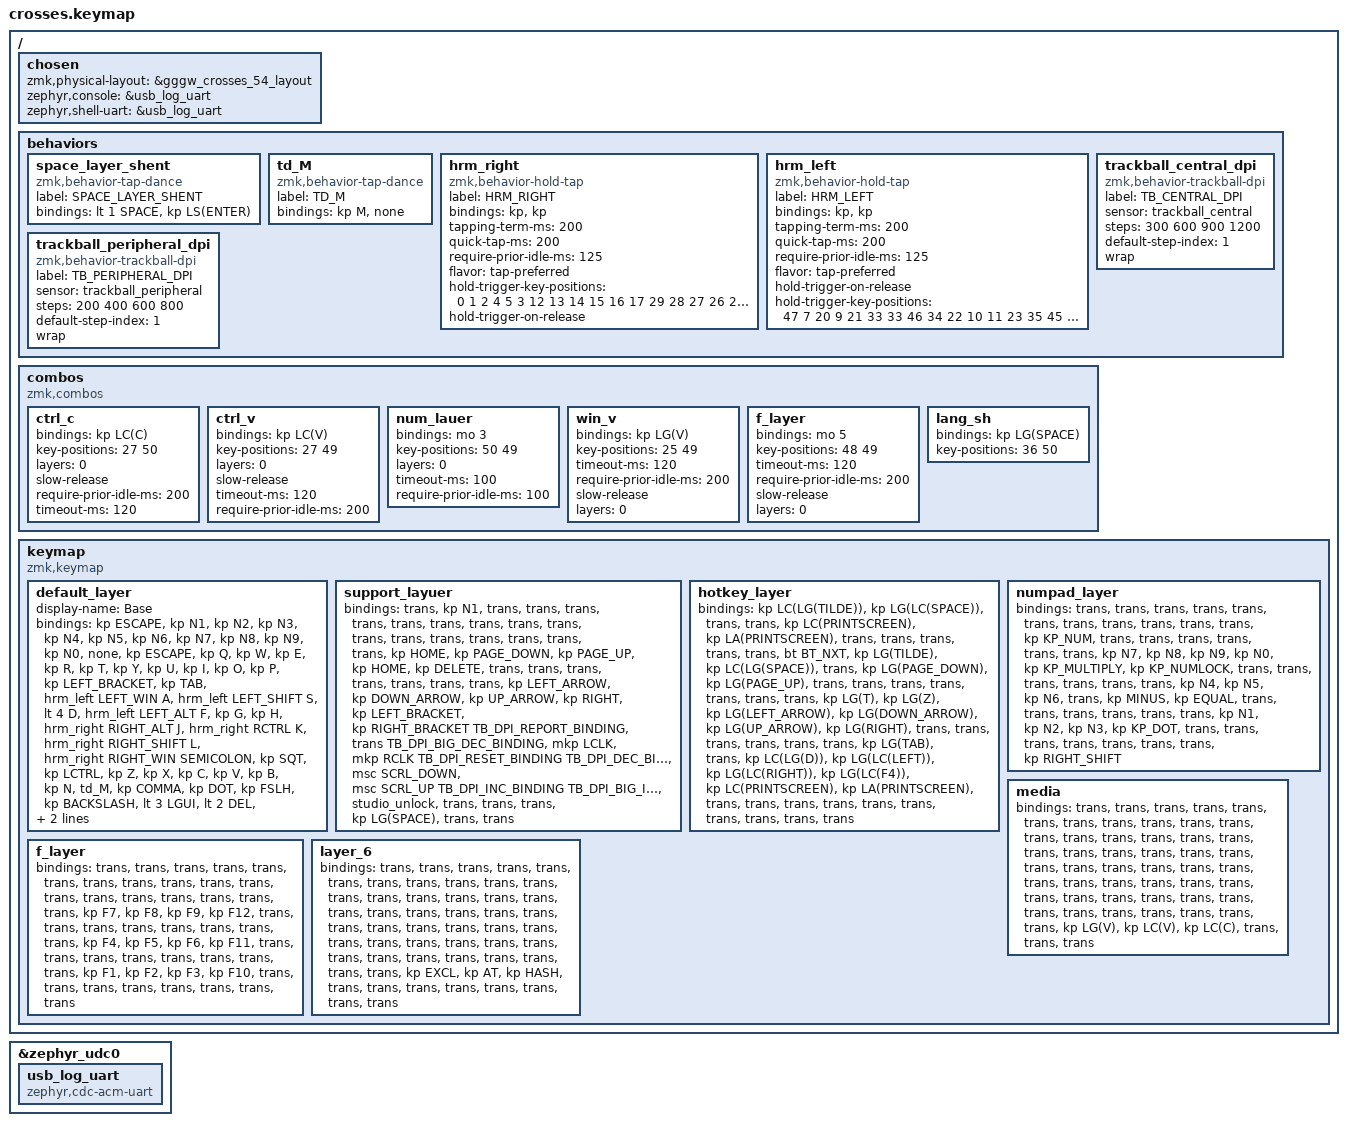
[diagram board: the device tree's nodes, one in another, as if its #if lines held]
#include <behaviors.dtsi>
#include <dt-bindings/zmk/bt.h>
#include <dt-bindings/zmk/keys.h>
#include <dt-bindings/zmk/pointing.h>
#include <dt-bindings/zmk/trackball_dpi.h>
#include <interfaces/hid-trackball.dtsi>

/ {
#define TB_DPI_BEHAVIOR &trans
#define TB_DPI_DEC_BINDING TB_DPI_BEHAVIOR
#define TB_DPI_INC_BINDING TB_DPI_BEHAVIOR
#define TB_DPI_RESET_BINDING TB_DPI_BEHAVIOR
#define TB_DPI_BIG_DEC_BINDING TB_DPI_BEHAVIOR
#define TB_DPI_BIG_INC_BINDING TB_DPI_BEHAVIOR
#define TB_DPI_REPORT_BINDING TB_DPI_BEHAVIOR

#if defined(CONFIG_ZMK_SPLIT_ROLE_CENTRAL)
#undef TB_DPI_BEHAVIOR
#undef TB_DPI_DEC_BINDING
#undef TB_DPI_INC_BINDING
#undef TB_DPI_RESET_BINDING
#undef TB_DPI_BIG_DEC_BINDING
#undef TB_DPI_BIG_INC_BINDING
#undef TB_DPI_REPORT_BINDING
#define TB_DPI_BEHAVIOR &trackball_central_dpi
#define TB_DPI_DEC_BINDING TB_DPI_BEHAVIOR ZMK_TRACKBALL_DPI_CMD_STEP_DOWN 1
#define TB_DPI_INC_BINDING TB_DPI_BEHAVIOR ZMK_TRACKBALL_DPI_CMD_STEP_UP 1
#define TB_DPI_RESET_BINDING TB_DPI_BEHAVIOR ZMK_TRACKBALL_DPI_CMD_RESET 0
#define TB_DPI_BIG_DEC_BINDING TB_DPI_BEHAVIOR ZMK_TRACKBALL_DPI_CMD_STEP_DOWN 2
#define TB_DPI_BIG_INC_BINDING TB_DPI_BEHAVIOR ZMK_TRACKBALL_DPI_CMD_STEP_UP 2
#define TB_DPI_REPORT_BINDING TB_DPI_BEHAVIOR ZMK_TRACKBALL_DPI_CMD_REPORT 0
#elif defined(CONFIG_ZMK_SPLIT_ROLE_PERIPHERAL)
#undef TB_DPI_BEHAVIOR
#undef TB_DPI_DEC_BINDING
#undef TB_DPI_INC_BINDING
#undef TB_DPI_RESET_BINDING
#undef TB_DPI_BIG_DEC_BINDING
#undef TB_DPI_BIG_INC_BINDING
#undef TB_DPI_REPORT_BINDING
#define TB_DPI_BEHAVIOR &trackball_peripheral_dpi
#define TB_DPI_DEC_BINDING TB_DPI_BEHAVIOR ZMK_TRACKBALL_DPI_CMD_STEP_DOWN 1
#define TB_DPI_INC_BINDING TB_DPI_BEHAVIOR ZMK_TRACKBALL_DPI_CMD_STEP_UP 1
#define TB_DPI_RESET_BINDING TB_DPI_BEHAVIOR ZMK_TRACKBALL_DPI_CMD_RESET 0
#define TB_DPI_BIG_DEC_BINDING TB_DPI_BEHAVIOR ZMK_TRACKBALL_DPI_CMD_STEP_DOWN 2
#define TB_DPI_BIG_INC_BINDING TB_DPI_BEHAVIOR ZMK_TRACKBALL_DPI_CMD_STEP_UP 2
#define TB_DPI_REPORT_BINDING TB_DPI_BEHAVIOR ZMK_TRACKBALL_DPI_CMD_REPORT 0
#endif

    chosen {
        zmk,physical-layout = &gggw_crosses_54_layout;
        zephyr,console = &usb_log_uart;
        zephyr,shell-uart = &usb_log_uart;
    };

    behaviors {
        space_layer_shent: space_layer_shent {
            compatible = "zmk,behavior-tap-dance";
            label = "SPACE_LAYER_SHENT";
            #binding-cells = <0>;
            bindings = <&lt 1 SPACE>, <&kp LS(ENTER)>;
        };

        td_M: td_M {
            compatible = "zmk,behavior-tap-dance";
            label = "TD_M";
            #binding-cells = <0>;
            bindings = <&kp M>, <&none>;
        };

        hrm_right: hrm_right {
            compatible = "zmk,behavior-hold-tap";
            label = "HRM_RIGHT";
            bindings = <&kp>, <&kp>;

            #binding-cells = <2>;
            tapping-term-ms = <200>;
            quick-tap-ms = <200>;
            require-prior-idle-ms = <125>;
            flavor = "tap-preferred";
            hold-trigger-key-positions = <0 1 2 4 5 3 12 13 14 15 16 17 29 28 27 26 25 24 36 37 38 39 40 41 48 49 50>;
            hold-trigger-on-release;
        };

        hrm_left: hrm_left {
            compatible = "zmk,behavior-hold-tap";
            label = "HRM_LEFT";
            bindings = <&kp>, <&kp>;

            #binding-cells = <2>;
            tapping-term-ms = <200>;
            quick-tap-ms = <200>;
            require-prior-idle-ms = <125>;
            flavor = "tap-preferred";
            hold-trigger-on-release;
            hold-trigger-key-positions = <47 7 20 9 21 33 33 46 34 22 10 11 23 35 45 8 32 44 43 42 30 31 19 18 6 51 52 53>;
        };

#if defined(CONFIG_SHIELD_CROSSES_RIGHT)
        trackball_central_dpi: trackball_central_dpi {
            compatible = "zmk,behavior-trackball-dpi";
            label = "TB_CENTRAL_DPI";
            #binding-cells = <2>;
            sensor = <&trackball_central>;
            steps = <300 600 900 1200>;
            default-step-index = <1>;
            wrap;
        };
#endif

#if defined(CONFIG_SHIELD_CROSSES_LEFT)
        trackball_peripheral_dpi: trackball_peripheral_dpi {
            compatible = "zmk,behavior-trackball-dpi";
            label = "TB_PERIPHERAL_DPI";
            #binding-cells = <2>;
            sensor = <&trackball_peripheral>;
            steps = <200 400 600 800>;
            default-step-index = <1>;
            wrap;
        };
#endif
    };

    combos {
        compatible = "zmk,combos";

        ctrl_c {
            bindings = <&kp LC(C)>;
            key-positions = <27 50>;
            layers = <0>;
            slow-release;
            require-prior-idle-ms = <200>;
            timeout-ms = <120>;
        };

        ctrl_v {
            bindings = <&kp LC(V)>;
            key-positions = <27 49>;
            layers = <0>;
            slow-release;
            timeout-ms = <120>;
            require-prior-idle-ms = <200>;
        };

        num_lauer {
            bindings = <&mo 3>;
            key-positions = <50 49>;
            layers = <0>;
            timeout-ms = <100>;
            require-prior-idle-ms = <100>;
        };

        win_v {
            bindings = <&kp LG(V)>;
            key-positions = <25 49>;
            timeout-ms = <120>;
            require-prior-idle-ms = <200>;
            slow-release;
            layers = <0>;
        };

        f_layer {
            bindings = <&mo 5>;
            key-positions = <48 49>;
            timeout-ms = <120>;
            require-prior-idle-ms = <200>;
            slow-release;
            layers = <0>;
        };

        lang_sh {
            bindings = <&kp LG(SPACE)>;
            key-positions = <36 50>;
        };
    };

    keymap {
        compatible = "zmk,keymap";

        default_layer {
            display-name = "Base";
            bindings = <
&kp ESCAPE  &kp N1                &kp N2                  &kp N3      &kp N4                &kp N5       &kp N6              &kp N7                  &kp N8              &kp N9                    &kp N0                          &none
&kp ESCAPE  &kp Q                 &kp W                   &kp E       &kp R                 &kp T        &kp Y               &kp U                   &kp I               &kp O                     &kp P                           &kp LEFT_BRACKET
&kp TAB     &hrm_left LEFT_WIN A  &hrm_left LEFT_SHIFT S  &lt 4 D     &hrm_left LEFT_ALT F  &kp G        &kp H               &hrm_right RIGHT_ALT J  &hrm_right RCTRL K  &hrm_right RIGHT_SHIFT L  &hrm_right RIGHT_WIN SEMICOLON  &kp SQT
&kp LCTRL   &kp Z                 &kp X                   &kp C       &kp V                 &kp B        &kp N               &td_M                   &kp COMMA           &kp DOT                   &kp FSLH                        &kp BACKSLASH
                                                          &lt 3 LGUI  &lt 2 DEL             &lt 1 ENTER  &space_layer_shent  &lt 3 BACKSPACE         &lt 0 A
            >;
        };

        support_layuer {
            bindings = <
&trans  &kp N1  &trans  &trans     &trans     &trans  &trans          &trans          &trans        &trans     &trans            &trans
&trans  &trans  &trans  &trans     &trans     &trans  &kp HOME        &kp PAGE_DOWN   &kp PAGE_UP   &kp HOME   &kp DELETE        &trans
&trans  &trans  &trans  &trans     &trans     &trans  &kp LEFT_ARROW  &kp DOWN_ARROW  &kp UP_ARROW  &kp RIGHT  &kp LEFT_BRACKET  &kp RIGHT_BRACKET
TB_DPI_REPORT_BINDING  &trans  TB_DPI_BIG_DEC_BINDING  &mkp LCLK  &mkp RCLK  TB_DPI_RESET_BINDING  TB_DPI_DEC_BINDING  &msc SCRL_DOWN  &msc SCRL_UP  TB_DPI_INC_BINDING  TB_DPI_BIG_INC_BINDING  &studio_unlock
                        &trans     &trans     &trans  &kp LG(SPACE)   &trans          &trans
            >;
        };

        hotkey_layer {
            bindings = <
&kp LC(LG(TILDE))  &kp LG(LC(SPACE))  &trans              &trans              &kp LC(PRINTSCREEN)  &kp LA(PRINTSCREEN)  &trans               &trans               &trans  &trans  &trans  &bt BT_NXT
&kp LG(TILDE)      &kp LC(LG(SPACE))  &trans              &kp LG(PAGE_DOWN)   &kp LG(PAGE_UP)      &trans               &trans               &trans               &trans  &trans  &trans  &trans
&kp LG(T)          &kp LG(Z)          &kp LG(LEFT_ARROW)  &kp LG(DOWN_ARROW)  &kp LG(UP_ARROW)     &kp LG(RIGHT)        &trans               &trans               &trans  &trans  &trans  &trans
&kp LG(TAB)        &trans             &kp LC(LG(D))       &kp LG(LC(LEFT))    &kp LG(LC(RIGHT))    &kp LG(LC(F4))       &kp LC(PRINTSCREEN)  &kp LA(PRINTSCREEN)  &trans  &trans  &trans  &trans
                                                          &trans              &trans               &trans               &trans               &trans               &trans
            >;
        };

        numpad_layer {
            bindings = <
&trans  &trans  &trans  &trans  &trans  &trans  &trans  &trans  &trans           &trans      &trans           &kp KP_NUM
&trans  &trans  &trans  &trans  &trans  &trans  &kp N7  &kp N8  &kp N9           &kp N0      &kp KP_MULTIPLY  &kp KP_NUMLOCK
&trans  &trans  &trans  &trans  &trans  &trans  &kp N4  &kp N5  &kp N6           &trans      &kp MINUS        &kp EQUAL
&trans  &trans  &trans  &trans  &trans  &trans  &kp N1  &kp N2  &kp N3           &kp KP_DOT  &trans           &trans
                        &trans  &trans  &trans  &trans  &trans  &kp RIGHT_SHIFT
            >;
        };

        media {
            bindings = <
&trans  &trans  &trans  &trans     &trans     &trans     &trans  &trans  &trans  &trans  &trans  &trans
&trans  &trans  &trans  &trans     &trans     &trans     &trans  &trans  &trans  &trans  &trans  &trans
&trans  &trans  &trans  &trans     &trans     &trans     &trans  &trans  &trans  &trans  &trans  &trans
&trans  &trans  &trans  &trans     &trans     &trans     &trans  &trans  &trans  &trans  &trans  &trans
                        &kp LG(V)  &kp LC(V)  &kp LC(C)  &trans  &trans  &trans
            >;
        };

        f_layer {
            bindings = <
&trans  &trans  &trans  &trans  &trans  &trans  &trans  &trans  &trans  &trans   &trans  &trans
&trans  &trans  &trans  &trans  &trans  &trans  &kp F7  &kp F8  &kp F9  &kp F12  &trans  &trans
&trans  &trans  &trans  &trans  &trans  &trans  &kp F4  &kp F5  &kp F6  &kp F11  &trans  &trans
&trans  &trans  &trans  &trans  &trans  &trans  &kp F1  &kp F2  &kp F3  &kp F10  &trans  &trans
                        &trans  &trans  &trans  &trans  &trans  &trans
            >;
        };

        layer_6 {
            bindings = <
&trans  &trans  &trans  &trans  &trans  &trans  &trans  &trans    &trans  &trans    &trans  &trans
&trans  &trans  &trans  &trans  &trans  &trans  &trans  &trans    &trans  &trans    &trans  &trans
&trans  &trans  &trans  &trans  &trans  &trans  &trans  &trans    &trans  &trans    &trans  &trans
&trans  &trans  &trans  &trans  &trans  &trans  &trans  &kp EXCL  &kp AT  &kp HASH  &trans  &trans
                        &trans  &trans  &trans  &trans  &trans    &trans
            >;
        };
    };
};

&zephyr_udc0 {
    usb_log_uart: usb_log_uart {
        compatible = "zephyr,cdc-acm-uart";
    };
};

&zephyr_udc0 {
    usb_log_uart: usb_log_uart {
        compatible = "zephyr,cdc-acm-uart";
    };
};
